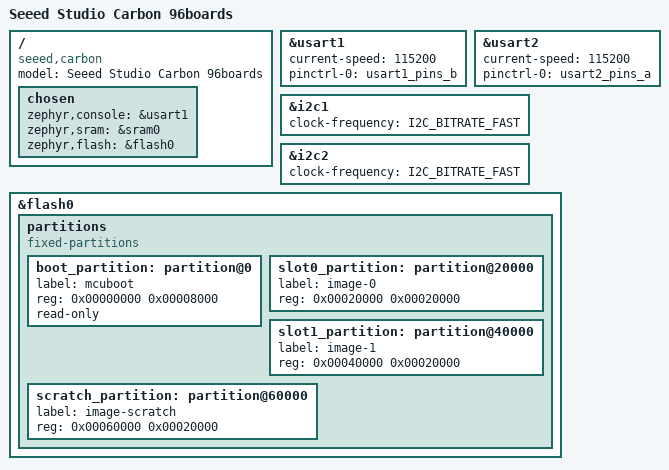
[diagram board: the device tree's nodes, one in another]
/*
 * Copyright (c) 2017 Linaro Limited
 *
 * SPDX-License-Identifier: Apache-2.0
 */

/dts-v1/;
#include <st/stm32f401.dtsi>

/ {
	model = "Seeed Studio Carbon 96boards";
	compatible = "seeed,carbon", "st,stm32f401";

	chosen {
		zephyr,console = &usart1;
		zephyr,sram = &sram0;
		zephyr,flash = &flash0;
	};
};

&usart1 {
	current-speed = <115200>;
	pinctrl-0 = <&usart1_pins_b>;
	pinctrl-names = "default";
	status = "ok";
};

&usart2 {
	current-speed = <115200>;
	pinctrl-0 = <&usart2_pins_a>;
	pinctrl-names = "default";
	status = "ok";
};

&i2c1 {
	status = "ok";
	clock-frequency = <I2C_BITRATE_FAST>;
};

&i2c2 {
	clock-frequency = <I2C_BITRATE_FAST>;
};

&flash0 {
	/*
	 * If chosen's zephyr,code-partition
	 * is unset, the image will be linked
	 * into the entire flash device.  If
	 * it points to an individual
	 * partition, the code will be linked
	 * to, and restricted to that
	 * partition.
	 */
	partitions {
		compatible = "fixed-partitions";
		#address-cells = <1>;
		#size-cells = <1>;

		boot_partition: partition@0 {
			label = "mcuboot";
			reg = <0x00000000 0x00008000>;
			read-only;
		};

		/*
		 * The flash starting at offset 0x00008000 and ending at
		 * offset 0x0001ffff (sectors 2 through 4) is reserved for
		 * use by the application.
		 */

		slot0_partition: partition@20000 {
			label = "image-0";
			reg = <0x00020000 0x00020000>;
		};
		slot1_partition: partition@40000 {
			label = "image-1";
			reg = <0x00040000 0x00020000>;
		};
		scratch_partition: partition@60000 {
			label = "image-scratch";
			reg = <0x00060000 0x00020000>;
		};
	};
};
